# RZN2L register map
Vendor: Renesas Electronics Corporation; Series: RZN; File version: 1.30.01
CPU: other r0p0, little endian, MPU, no FPU, VTOR, 4 interrupt priority bits, 624 interrupts
Registers are 32-bit, read-write, reset 0x0 unless marked. A register's access mark holds for its fields unless they carry their own. Offsets are from the block's base; [hi:lo] are bit positions.

## SHOSTIF — Serial Host Interface
Base 0x80241000
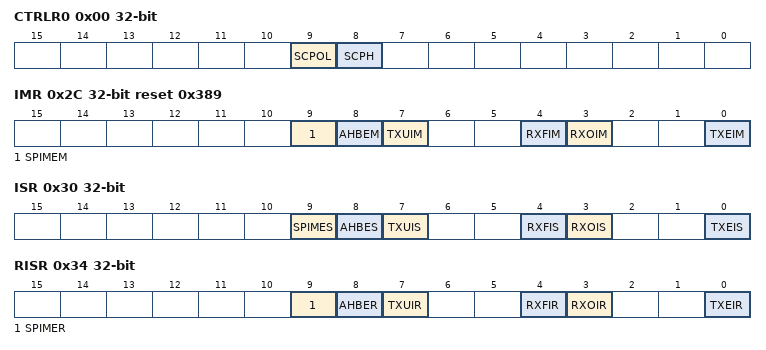
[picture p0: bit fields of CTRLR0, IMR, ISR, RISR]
0x00 CTRLR0 — Control Register 0
  [9] SCPOL — Serial Clock Polarity
    0=Inactive state of the serial clock is low; 1=Inactive state of the serial clock is high
  [8] SCPH — Serial Clock Phase
    0=Serial clock toggles in the middle of the first bit; 1=Serial clock toggles at the start of the first bit
0x08 ENR — Enable Register
  [0] ENABLE — SHOSTIF Enable
    0=Disables SHOSTIF; 1=Enables SHOSTIF
0x14 RXFBTR reset 0x3F — Receive FIFO Burst Threshold Register
  [5:0] RXFBTL — Receive FIFO Burst Threshold
0x18 TXFTLR — Transmit FIFO Threshold Level Register
  [5:0] TFT — Transmit FIFO Threshold
0x1C RXFTLR — Receive FIFO Threshold Level Register
  [5:0] RFT — Receive FIFO Threshold
0x28 SR ro — Status Register
  [0] BUSY — Busy Flag
    0=SHOSTIF is idle or disabled; 1=SHOSTIF is actively transferring data
0x2C IMR reset 0x389 — Interrupt Mask Register
  [9] SPIMEM — SPI Master Error Interrupt Mask
    0=spime_intr interrupt is masked; 1=spime_intr interrupt is not masked
  [8] AHBEM — AHB Error Interrupt Mask
    0=ahbe_intr interrupt is masked; 1=ahbe_intr interrupt is not masked
  [7] TXUIM — Transmit FIFO Underflow Mask
    0=txu_intr interrupt is masked; 1=txu_intr interrupt is not masked
  [4] RXFIM — Receive FIFO Full Interrupt Mask
    0=rxf_intr interrupt is masked; 1=rxf_intr interrupt is not masked
  [3] RXOIM — Receive FIFO Overflow Interrupt Mask
    0=rxo_intr interrupt is masked; 1=rxo_intr interrupt is not masked
  [0] TXEIM — Transmit FIFO Empty Interrupt Mask
    0=txe_intr interrupt is masked; 1=txe_intr interrupt is not masked
0x30 ISR ro (reset mask 0xFFFFFFFE) — Interrupt Status Register
  [9] SPIMES — SPI Master Error Interrupt Status
    0=spime_intr interrupt is not active after masking; 1=spime_intr interrupt is active after masking
  [8] AHBES — AHB Error Interrupt Status
    0=ahbe_intr interrupt is not active after masking; 1=ahbe_intr interrupt is active after masking
  [7] TXUIS — Transmit FIFO Underflow Status
    0=txu_intr interrupt is not active after masking; 1=txu_intr interrupt is active after masking
  [4] RXFIS — Receive FIFO Full Interrupt Status
    0=rxf_intr interrupt is not active after masking; 1=rxf_intr interrupt is active after masking
  [3] RXOIS — Receive FIFO Overflow Interrupt Status
    0=rxo_intr interrupt is not active after masking; 1=rxo_intr interrupt is active after masking
  [0] TXEIS — Transmit FIFO Empty Interrupt Status
    0=txe_intr interrupt is not active after masking; 1=txe_intr interrupt is active after masking
0x34 RISR ro (reset mask 0xFFFFFFFE) — Raw Interrupt Status Register
  [9] SPIMER — SPI Master Error Raw Interrupt Status
    0=spime_intr interrupt is not active prior to masking; 1=spime_intr interrupt is active prior to masking
  [8] AHBER — AHB Error Raw Interrupt Status
    0=ahbe_intr interrupt is not active prior to masking; 1=ahbe_intr interrupt is active prior to masking
  [7] TXUIR — Transmit FIFO Underflow Raw Interrupt Status
    0=txu_intr interrupt is not active prior to masking; 1=txu_intr interrupt is active prior to masking
  [4] RXFIR — Receive FIFO Full Raw Interrupt Status
    0=rxf_intr interrupt is not active prior to masking; 1=rxf_intr interrupt is active prior to masking
  [3] RXOIR — Receive FIFO Overflow Raw Interrupt Status
    0=rxo_intr interrupt is not active prior to masking; 1=rxo_intr interrupt is active prior to masking
  [0] TXEIR — Transmit FIFO Empty Raw Interrupt Status
    0=txe_intr interrupt is not active prior to masking; 1=txe_intr interrupt is active prior to masking
0x38 TXUICR ro — Transmit FIFO Underflow Interrupt Clear Register
  [0] TXUICR — Clear Transmit FIFO Underflow Interrupt
0x3C RXOICR ro — Receive FIFO Overflow Interrupt Clear Register
  [0] RXOICR — Clear Receive FIFO Overflow Interrupt
0x40 SPIMECR ro — SPI Master Interrupt Clear Register
  [0] SPIMECR — Clear SPI Master Error interrupt
0x44 AHBECR ro — AHB Error Clear Register
  [0] AHBECR — Clear AHB Error Interrupt
0x48 ICR ro — Interrupt Clear Register
  [0] ICR — Clear Interrupts
